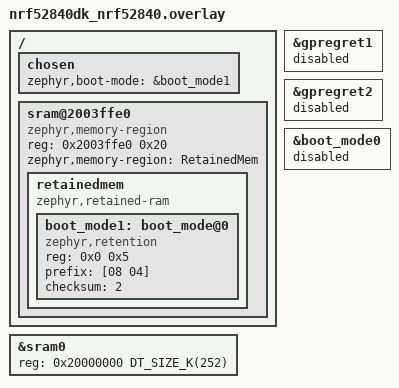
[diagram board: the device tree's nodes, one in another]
/*
 * Copyright (c) 2026 The Zephyr Project Contributors
 *
 * SPDX-License-Identifier: Apache-2.0
 */

/ {
	chosen {
		zephyr,boot-mode = &boot_mode1;
	};

	sram@2003ffe0 {
		compatible = "zephyr,memory-region", "mmio-sram";
		reg = <0x2003ffe0 0x20>;
		ranges = <0x0 0x2003ffe0 0x20>;
		#address-cells = <1>;
		#size-cells = <1>;
		zephyr,memory-region = "RetainedMem";
		status = "okay";

		retainedmem {
			compatible = "zephyr,retained-ram";
			ranges;
			#address-cells = <1>;
			#size-cells = <1>;
			status = "okay";

			boot_mode1: boot_mode@0 {
				compatible = "zephyr,retention";
				reg = <0x0 0x5>;
				prefix = [08 04];
				checksum = <2>;
				status = "okay";
			};
		};
	};
};

&gpregret1 {
	status = "disabled";
};

&gpregret2 {
	status = "disabled";
};

&sram0 {
	reg = <0x20000000 DT_SIZE_K(252)>;
};

&boot_mode0 {
	status = "disabled";
};
